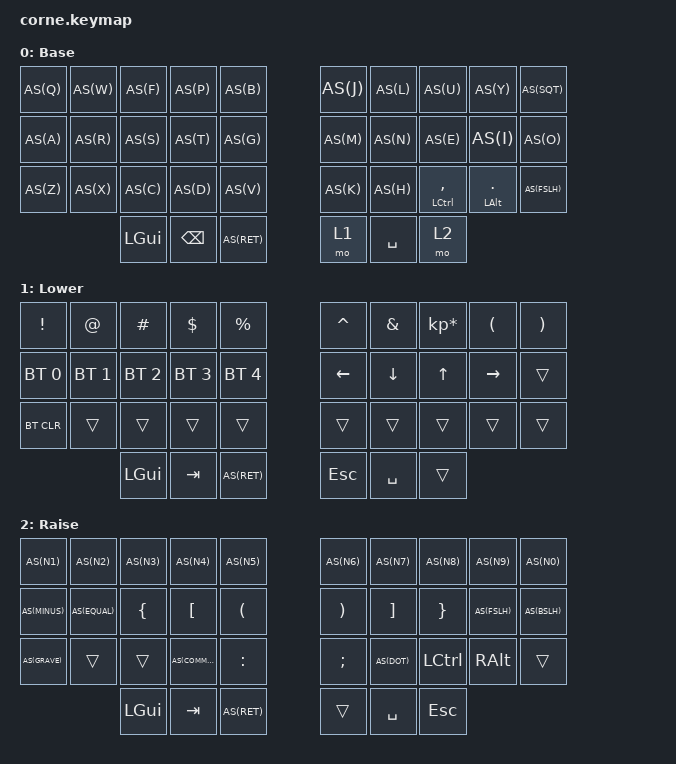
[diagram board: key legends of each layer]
/*
 * Copyright (c) 2020 The ZMK Contributors
 *
 * SPDX-License-Identifier: MIT
 */

#include <behaviors.dtsi>
#include <dt-bindings/zmk/keys.h>
#include <dt-bindings/zmk/bt.h>


#define AS(keycode) &as LS(keycode) keycode

/ {
    chosen {
        zmk,physical-layout = &foostan_corne_5col_layout;
    };

    behaviors {
        as: auto_shift {
            compatible = "zmk,behavior-hold-tap";
            #binding-cells = <2>;
            tapping_term_ms = <200>;
            quick_tap_ms = <0>;
            flavor = "tap-preferred";
            bindings = <&kp>, <&kp>;
        };
    };
        keymap {
                compatible = "zmk,keymap";

                default_layer {
// -----------------------------------------------------------------------------------------
// THIS HAS BEEN MAPPED TO COLEMAK-DH
// |  Q  |  W  |  E  |  R  |  T  |     |  Y  |  U   |  I   |  O   | P ' |
// |  A  |  S  |  D  |  F  |  G  |     |  H  |  J   |  K   |  L   | ' | 
// |  Z  |  X  |  C  |  V  |  B  |     |  N  |  M   | CTRL/, | META/. | / |
//             | GUI | LWR | RSE |     | SPC | ENT  | BSPC |
                        display-name = "Base";
                        bindings = <
   AS(Q) AS(W) AS(F) AS(P) AS(B)     AS(J)     AS(L)   AS(U)            AS(Y)          AS(SQT)
   AS(A) AS(R) AS(S) AS(T) AS(G)     AS(M)     AS(N)   AS(E)            AS(I)          AS(O)
   AS(Z) AS(X) AS(C) AS(D) AS(V)     AS(K)     AS(H)   &mt LCTRL COMMA  &mt LALT  DOT  AS(FSLH)
            &kp LGUI &kp BSPC AS(RET)  &mo 1 &kp SPACE &mo 2
                        >;
                };

                lower_layer {
// -----------------------------------------------------------------------------------------
// | !     |  @  |  #  |  $  |  %  |     |  ^  |  &  |  *  |  (  |  )  |
// | BT1   | BT2 | BT3 | BT4 | BT5 |     | LFT | DWN |  UP | RGT |     |
// | BTCLR |     |     |     |     |     |     |     |     |     |     |
//               | GUI | ESC |     |     | SPC | RET | TAB |
                        display-name = "Lower";
                        bindings = <
   &kp EXCL     &kp AT       &kp HASH     &kp DLLR     &kp PRCNT        &kp CARET &kp AMPS  &kp KP_MULTIPLY &kp LPAR  &kp RPAR
   &bt BT_SEL 0 &bt BT_SEL 1 &bt BT_SEL 2 &bt BT_SEL 3 &bt BT_SEL 4     &kp LEFT  &kp DOWN  &kp UP          &kp RIGHT &trans 
   &bt BT_CLR   &trans       &trans       &trans       &trans           &trans    &trans    &trans          &trans    &trans 
                             &kp LGUI     &kp TAB      AS(RET)          &kp ESC   &kp SPACE &trans
                        >;
                };

                raise_layer {
// -----------------------------------------------------------------------------------------
// | 1! |  2@ |  3# |  4$ |  5% |     |  6^ |  7& |  8* |  9(  |  0)  |
// | -_ |  =+ |  {  |  [  |  (  |     |  )  |  ]  |  }  |  /?  |  \|  |
// | `~ |     |     |  ,< |  :  |     |  ;  |  .> | CTRL| META |      |
//            | GUI |     | ESC |     | SPC | ENT | TAB |
                        display-name = "Raise";
                        bindings = <

   AS(N1)    AS(N2)    AS(N3)    AS(N4)    AS(N5)        AS(N6)    AS(N7)    AS(N8)    AS(N9)   AS(N0)
   AS(MINUS) AS(EQUAL) &kp LBRC  &kp LBKT  &kp LPAR      &kp RPAR  &kp RBKT  &kp RBRC  AS(FSLH) AS(BSLH)
   AS(GRAVE) &trans    &trans    AS(COMMA) &kp COLON     &kp SEMI  AS(DOT)   &kp LCTRL &kp RALT &trans
                       &kp LGUI  &kp TAB   AS(RET)       &trans    &kp SPACE &kp ESC
                        >;
                };

                extra_1 {
                        status = "reserved";
                };

                extra_2 {
                        status = "reserved";
                };

                extra_3 {
                        status = "reserved";
                };
        };
};
